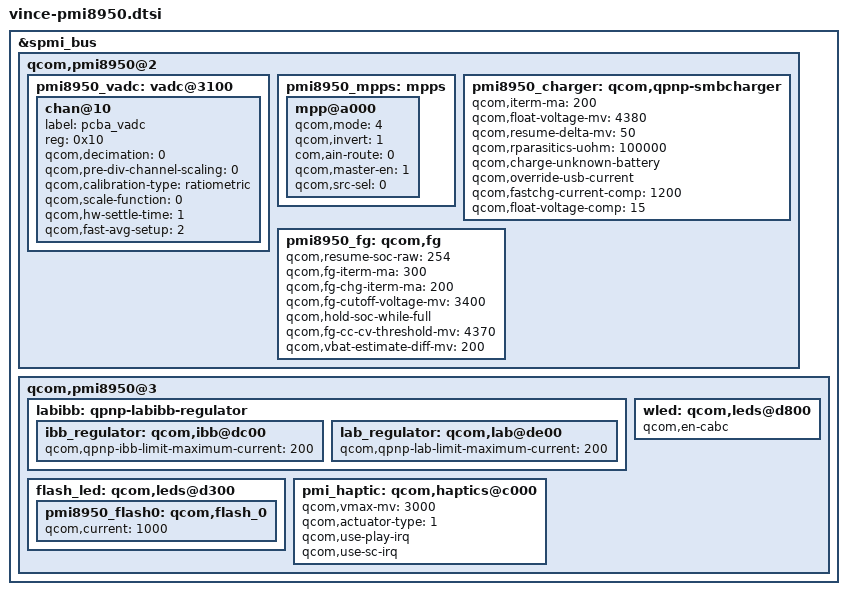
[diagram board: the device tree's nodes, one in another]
/* Copyright (c) 2015-2017, The Linux Foundation. All rights reserved.
 *
 * This program is free software; you can redistribute it and/or modify
 * it under the terms of the GNU General Public License version 2 and
 * only version 2 as published by the Free Software Foundation.
 *
 * This program is distributed in the hope that it will be useful,
 * but WITHOUT ANY WARRANTY; without even the implied warranty of
 * MERCHANTABILITY or FITNESS FOR A PARTICULAR PURPOSE.  See the
 * GNU General Public License for more details.
 */

&spmi_bus {
	qcom,pmi8950@2 {
		pmi8950_vadc: vadc@3100 {
			chan@10 {
				label = "pcba_vadc";
				reg = <0x10>;
				qcom,decimation = <0>;
				qcom,pre-div-channel-scaling = <0>; //1:1
				qcom,calibration-type = "ratiometric";
				qcom,scale-function = <0>;
				qcom,hw-settle-time = <1>;
				qcom,fast-avg-setup = <2>;
			};
		};
		pmi8950_mpps: mpps {
			mpp@a000 {
				qcom,mode = <4>; /* AIN input */
				qcom,invert = <1>; /* Enable MPP */
				com,ain-route = <0>; /* AMUX 5 */
				qcom,master-en = <1>;
				qcom,src-sel = <0>; /* Function constant */
				status = "okay";
			};
		};
		pmi8950_charger: qcom,qpnp-smbcharger {
			qcom,iterm-ma = <200>;
			qcom,float-voltage-mv = <4380>;
			qcom,resume-delta-mv = <50>;
			/delete-property/ qcom,rparasitic-uohm;
			qcom,rparasitics-uohm = <100000>;
			qcom,charge-unknown-battery;
			/delete-property/ qcom,parallel-usb-min-current-ma;
			/delete-property/ qcom,parallel-usb-9v-min-current-ma;
			/delete-property/ qcom,parallel-allowed-lowering-ma;
			qcom,override-usb-current;
			qcom,fastchg-current-comp = <1200>;
			qcom,float-voltage-comp = <15>;
			/delete-property/ qcom,autoadjust-vfloat;
		};
		pmi8950_fg: qcom,fg {
			/delete-property/ qcom,resume-soc;
			qcom,resume-soc-raw = <254>;
			qcom,fg-iterm-ma = <300>;
			qcom,fg-chg-iterm-ma = <200>;
			qcom,fg-cutoff-voltage-mv = <3400>;
			qcom,hold-soc-while-full;
			qcom,fg-cc-cv-threshold-mv =<4370>;
			qcom,vbat-estimate-diff-mv = <200>;
		};
	};

	qcom,pmi8950@3 {
		labibb: qpnp-labibb-regulator {
			status = "ok";
			ibb_regulator: qcom,ibb@dc00 {
				qcom,qpnp-ibb-limit-maximum-current = <200>;
			};
			lab_regulator: qcom,lab@de00 {
				qcom,qpnp-lab-limit-maximum-current = <200>;
			};
		};
		wled: qcom,leds@d800 {
			qcom,en-cabc;
		};
		flash_led: qcom,leds@d300 {
			pmi8950_flash0: qcom,flash_0 {
				qcom,current = <1000>;
			};
		};
		pmi_haptic: qcom,haptics@c000 {
			qcom,vmax-mv = <3000>;
			qcom,actuator-type = <1>;
			qcom,use-play-irq;
			qcom,use-sc-irq;
		};
	};
};
